# Timer_Event_Control_2 register map
Vendor: Texas Instruments
Peripheral module from a debugger description file (folder msp430).
Registers are 16-bit, read-write, reset 0x0 unless marked. A register's access mark holds for its fields unless they carry their own. Offsets are as the file gives them; lines under a group give offsets from that group; [hi:lo] are bit positions; {n}, {i} and the like mark numbered series; 'fields as' and 'values as' point back to an identical list; <NAME> marks a mode.

## Timer_Event_Control
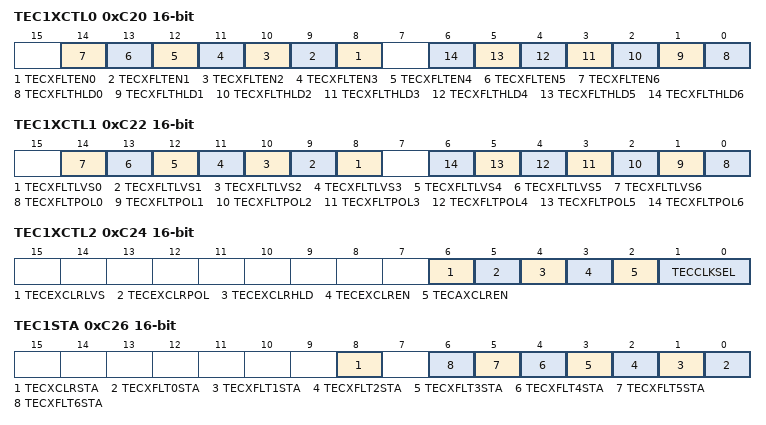
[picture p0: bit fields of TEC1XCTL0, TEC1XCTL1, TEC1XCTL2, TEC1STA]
0xC20 TEC1XCTL0 — Timer Event Control 1 External Control 0
  [n+8] TECXFLTEN{n} (n=0..6) — TEV Ext. fault signal enable for CE{n}
  [n] TECXFLTHLD{n} (n=0..6) — TEV Ext. fault signal hold for CE{n}
0xC22 TEC1XCTL1 — Timer Event Control 1 External Control 1
  [n+8] TECXFLTLVS{n} (n=0..6) — TEV Signal Type of Ext. fault {n}
  [n] TECXFLTPOL{n} (n=0..6) — TEV Polarity Bit of ext. fault {n}
0xC24 TEC1XCTL2 — Timer Event Control 1 External Control 2
  [6] TECEXCLRLVS — TEV Signal Type of Ext. clear
  [5] TECEXCLRPOL — TEV Polarity Bit of ext. clear
  [4] TECEXCLRHLD — TEV External clear signal hold bit
  [3] TECEXCLREN — TEV Ext. clear signal control
  [2] TECAXCLREN — TEV Auxilary clear signal control
  [1:0] TECCLKSEL — TEV Aux. Clock Select Bit: 0
    {v}=TEV Aux. Clock Select: CLK{v} (v=0..3)
0xC26 TEC1STA — Timer Event Control 1 Status
  [8] TECXCLRSTA — TEC External clear status flag
  [n] TECXFLT{n}STA (n=0..6) — TEV External fault status flag for CE{n}
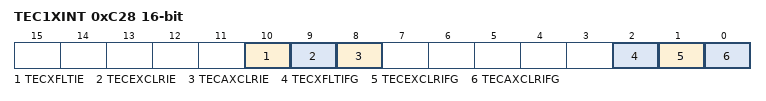
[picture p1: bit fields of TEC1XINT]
0xC28 TEC1XINT — Timer Event Control 1 External Interrupt
  [10] TECXFLTIE — TEC External Fault Interrupt Enable
  [9] TECEXCLRIE — TEC External Clear Interrupt Enable
  [8] TECAXCLRIE — TEC Aux. Clear Interrupt Enable
  [2] TECXFLTIFG — TEC External Fault Interrupt Flag
  [1] TECEXCLRIFG — TEC External Clear Interrupt Flag
  [0] TECAXCLRIFG — TEC Aux. Clear Interrupt Flag
0xC2A TEC1IV access not given reset not defined — Timer Event Control 1 Interrupt Vector
